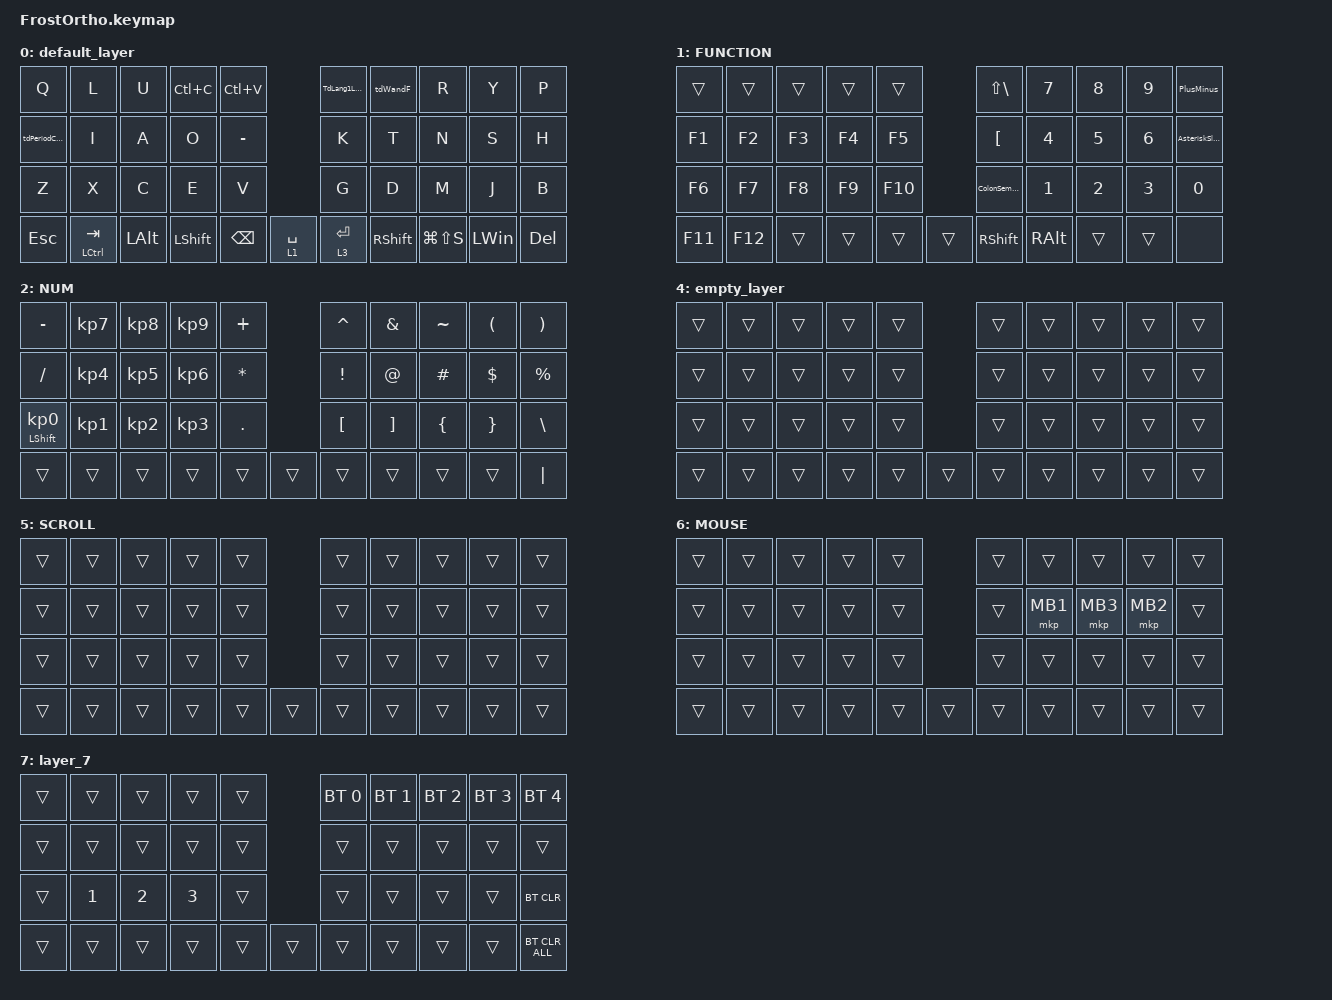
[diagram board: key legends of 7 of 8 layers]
#include <input/processors.dtsi>
#include <behaviors.dtsi>
#include <dt-bindings/zmk/bt.h>
#include <dt-bindings/zmk/keys.h>
#include <dt-bindings/zmk/pointing.h>

&mt {
    flavor = "balanced";
    quick-tap-ms = <0>;
};

&mkp_input_listener { input-processors = <&zip_temp_layer 6 10000>; };

/ {
    combos {
        compatible = "zmk,combos";

        Alt_tab {
            bindings = <&kp LA(TAB)>;
            key-positions = <12 13>;
        };

        Ctrl_Z {
            bindings = <&kp LC(Z)>;
            key-positions = <12 11>;
        };

        Ctrl_P {
            bindings = <&kp LC(P)>;
            key-positions = <14 13>;
        };

        Ctrl_S {
            bindings = <&kp LC(S)>;
            key-positions = <10 14>;
        };
    };

    behaviors {
        tdPeriodComma: tdPeriodComma {
            compatible = "zmk,behavior-tap-dance";
            label = "TDPERIODCOMMA";
            #binding-cells = <0>;
            bindings = <&kp COMMA>, <&kp PERIOD>;
        };

        tdWandF: tdWandF {
            compatible = "zmk,behavior-tap-dance";
            label = "TDWANDF";
            #binding-cells = <0>;
            bindings = <&kp W>, <&kp F>;
            tapping-term-ms = <150>;
        };

        PlusMinus: PlusMinus {
            compatible = "zmk,behavior-tap-dance";
            label = "PLUSMINUS";
            #binding-cells = <0>;
            bindings = <&kp LS(SEMI)>, <&kp MINUS>;
            tapping-term-ms = <200>;
        };

        AsteriskSlash: AsteriskSlash {
            compatible = "zmk,behavior-tap-dance";
            label = "ASTERISKSLASH";
            #binding-cells = <0>;
            tapping-term-ms = <200>;
            bindings = <&kp LS(SINGLE_QUOTE)>, <&kp SLASH>;
        };

        ColonSemicolon: ColonSemicolon {
            compatible = "zmk,behavior-tap-dance";
            label = "COLONSEMICOLON";
            #binding-cells = <0>;
            tapping-term-ms = <200>;
            bindings = <&kp APOS>, <&kp SEMI>;
        };

        TdLang1Lang2: TdLang1Lang2 {
            compatible = "zmk,behavior-tap-dance";
            label = "TDLANG1LANG2";
            #binding-cells = <0>;
            bindings = <&kp LANGUAGE_1>, <&kp LANG2>;
        };
    };

    keymap {
        compatible = "zmk,keymap";  

        default_layer {
            bindings = <
&kp Q           &kp L          &kp U         &kp LC(C)       &kp LC(V)                           &TdLang1Lang2    &tdWandF         &kp R   &kp Y   &kp P
&tdPeriodComma  &kp I          &kp A         &kp O           &kp MINUS                           &kp K            &kp T            &kp N   &kp S   &kp H
&kp Z           &kp X          &kp C         &kp E           &kp V                               &kp G            &kp D            &kp M   &kp J   &kp B
&kp ESC         &mt LCTRL TAB  &kp LEFT_ALT  &kp LEFT_SHIFT  &kp BACKSPACE  &lt 1 SPACE          &lt 3 ENTER      &kp RIGHT_SHIFT  &kp LG(LS(S))  &kp LEFT_WIN  &kp DEL
            >;

            sensor-bindings = <&inc_dec_kp PG_UP PAGE_DOWN>;
        };

        FUNCTION {
            bindings = <
&trans   &trans   &trans  &trans  &trans              &kp LS(BACKSLASH)  &kp N7  &kp N8  &kp N9  &PlusMinus
&kp F1   &kp F2   &kp F3  &kp F4  &kp F5              &kp LEFT_BRACKET   &kp N4  &kp N5  &kp N6  &AsteriskSlash
&kp F6   &kp F7   &kp F8  &kp F9  &kp F10             &ColonSemicolon    &kp N1  &kp N2  &kp N3  &kp N0
&kp F11  &kp F12  &trans  &trans  &trans  &trans       &kp RIGHT_SHIFT    &kp RIGHT_ALT  &trans  &trans  &none
            >;

            sensor-bindings = <&inc_dec_kp PG_UP PAGE_DOWN>;
        };

        NUM {
            bindings = <
&kp MINUS                   &kp KP_NUMBER_7  &kp KP_NUMBER_8  &kp KP_NUMBER_9  &kp PLUS              &kp CARET          &kp AMPERSAND      &kp TILDE       &kp LEFT_PARENTHESIS  &kp RIGHT_PARENTHESIS
&kp SLASH                   &kp KP_NUMBER_4  &kp KP_NUMBER_5  &kp KP_NUMBER_6  &kp ASTERISK          &kp EXCLAMATION    &kp AT_SIGN        &kp HASH        &kp DOLLAR            &kp PERCENT
&mt LEFT_SHIFT KP_NUMBER_0  &kp KP_NUMBER_1  &kp KP_NUMBER_2  &kp KP_NUMBER_3  &kp PERIOD            &kp LEFT_BRACKET   &kp RIGHT_BRACKET  &kp LEFT_BRACE  &kp RIGHT_BRACE       &kp BACKSLASH
&trans                      &trans           &trans           &trans           &trans     &trans      &trans             &trans             &trans          &trans                &kp PIPE
            >;

            sensor-bindings = <&inc_dec_kp PG_UP PAGE_DOWN>;
        };

        ARROW {
            bindings = <
&kp ESCAPE      &kp LC(LS(TAB))         &kp UP_ARROW    &kp ASTERISK             &kp LEFT_PARENTHESIS              &trans  &trans  &trans  &trans  &trans
&kp HOME        &kp LEFT_ARROW          &kp DOWN_ARROW  &kp RIGHT_ARROW          &kp END               &trans      &trans  &trans  &trans  &trans  &trans
&kp LEFT_SHIFT  &kp LG(LS(LEFT_ARROW))  &trans          &kp LG(LS(RIGHT_ARROW))  &trans                &trans      &trans  &trans  &trans  &trans  &trans
&trans          &trans                  &trans          &trans                   &trans     &trans      &trans      &trans  &trans  &trans  &kp RCTRL
            >;

            sensor-bindings = <&inc_dec_kp LC(PAGE_UP) LC(PAGE_DOWN)>;
        };

        empty_layer {
            bindings = <
&trans  &trans  &trans  &trans  &trans              &trans  &trans  &trans  &trans  &trans
&trans  &trans  &trans  &trans  &trans              &trans  &trans  &trans  &trans  &trans
&trans  &trans  &trans  &trans  &trans              &trans  &trans  &trans  &trans  &trans
&trans  &trans  &trans  &trans  &trans  &trans      &trans  &trans  &trans  &trans  &trans
            >;

            sensor-bindings = <&inc_dec_kp PG_UP PAGE_DOWN>;
        };

        SCROLL {
            bindings = <
&trans  &trans  &trans  &trans  &trans              &trans  &trans  &trans  &trans  &trans
&trans  &trans  &trans  &trans  &trans              &trans  &trans  &trans  &trans  &trans
&trans  &trans  &trans  &trans  &trans              &trans  &trans  &trans  &trans  &trans
&trans  &trans  &trans  &trans  &trans  &trans      &trans  &trans  &trans  &trans  &trans
            >;

            sensor-bindings = <&inc_dec_kp PG_UP PAGE_DOWN>;
        };

        MOUSE {
            bindings = <
&trans  &trans  &trans  &trans  &trans              &trans  &trans    &trans    &trans    &trans
&trans  &trans  &trans  &trans  &trans              &trans  &mkp MB1  &mkp MB3  &mkp MB2  &trans
&trans  &trans  &trans  &trans  &trans              &trans  &trans    &trans    &trans    &trans
&trans  &trans  &trans  &trans  &trans  &trans      &trans  &trans    &trans    &trans    &trans
            >;

            sensor-bindings = <&inc_dec_kp PG_UP PAGE_DOWN>;
        };

        layer_7 {
            bindings = <
&trans  &trans        &trans        &trans        &trans              &bt BT_SEL 0  &bt BT_SEL 1  &bt BT_SEL 2  &bt BT_SEL 3  &bt BT_SEL 4
&trans  &trans        &trans        &trans        &trans              &trans        &trans        &trans        &trans        &trans
&trans  &kp NUMBER_1  &kp NUMBER_2  &kp NUMBER_3  &trans              &trans        &trans        &trans        &trans        &bt BT_CLR
&trans  &trans        &trans        &trans        &trans  &trans      &trans        &trans        &trans        &trans        &bt BT_CLR_ALL
            >;

            sensor-bindings = <&inc_dec_kp PG_UP PAGE_DOWN>;
        };
    };
};
